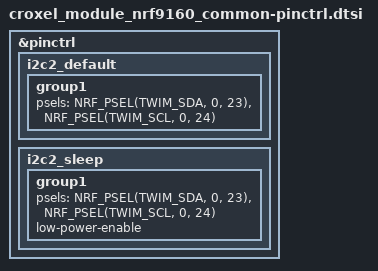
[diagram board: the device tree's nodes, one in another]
&pinctrl {
    i2c2_default: i2c2_default {
        group1 {
            psels = <NRF_PSEL(TWIM_SDA, 0, 23)>,
                <NRF_PSEL(TWIM_SCL, 0, 24)>;
        };
    };
    i2c2_sleep: i2c2_sleep {
        group1 {
            psels = <NRF_PSEL(TWIM_SDA, 0, 23)>,
                <NRF_PSEL(TWIM_SCL, 0, 24)>;
            low-power-enable;
        };
    };
};
